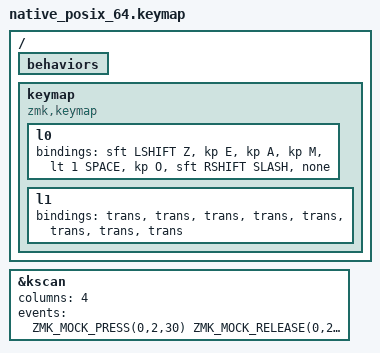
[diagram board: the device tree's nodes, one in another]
// Shift on Z and / with the real sft hold-tap: Shift with any other key,
// the key's own character only on a quick lone tap; a lone hold stays Shift.
// Shift goes down at key press (hold-while-undecided), so a tap is Shift, then z.
// Mock positions: row 0 = Z (sft LSHIFT), E, A, M; row 1 = Space (&lt 1), O, / (sft RSHIFT).
#include <dt-bindings/zmk/keys.h>
#include <behaviors.dtsi>
#include <dt-bindings/zmk/kscan_mock.h>

#include "real/&lt.dtsi"

/ {
    behaviors {
#include "real/sft.dtsi"
    };

    keymap {
        compatible = "zmk,keymap";
        l0 { bindings = <&sft LSHIFT Z &kp E &kp A &kp M &lt 1 SPACE &kp O &sft RSHIFT SLASH &none>; };
        l1 { bindings = <&trans &trans &trans &trans &trans &trans &trans &trans>; };
    };
};

&kscan {
    columns = <4>;
    events = <
        /* 1: a, Space tap, Z held 60 ms after Space up, tap O -> a, space, Shift+O */
        ZMK_MOCK_PRESS(0,2,30) ZMK_MOCK_RELEASE(0,2,40) ZMK_MOCK_PRESS(1,0,60) ZMK_MOCK_RELEASE(1,0,60)
        ZMK_MOCK_PRESS(0,0,50) ZMK_MOCK_PRESS(1,1,30) ZMK_MOCK_RELEASE(1,1,30) ZMK_MOCK_RELEASE(0,0,300)
        /* 2: a, then Z held as E (same hand) goes down -> a, Shift+E */
        ZMK_MOCK_PRESS(0,2,30) ZMK_MOCK_RELEASE(0,2,60) ZMK_MOCK_PRESS(0,0,40) ZMK_MOCK_PRESS(0,1,20)
        ZMK_MOCK_RELEASE(0,0,20) ZMK_MOCK_RELEASE(0,1,300)
        /* 3: a, then Z held as O (other hand) goes down -> a, Shift+O */
        ZMK_MOCK_PRESS(0,2,30) ZMK_MOCK_RELEASE(0,2,60) ZMK_MOCK_PRESS(0,0,40) ZMK_MOCK_PRESS(1,1,20)
        ZMK_MOCK_RELEASE(0,0,20) ZMK_MOCK_RELEASE(1,1,300)
        /* 4: idle, Z held, tap M -> Shift+M */
        ZMK_MOCK_PRESS(0,0,50) ZMK_MOCK_PRESS(0,3,30) ZMK_MOCK_RELEASE(0,3,30) ZMK_MOCK_RELEASE(0,0,300)
        /* 5: Z tapped alone -> Shift down and up, then z */
        ZMK_MOCK_PRESS(0,0,50) ZMK_MOCK_RELEASE(0,0,300)
        /* 6: Z held alone 400 ms, then released -> Shift only, no z */
        ZMK_MOCK_PRESS(0,0,400) ZMK_MOCK_RELEASE(0,0,300)
        /* 7: Z released before O goes down -> z o */
        ZMK_MOCK_PRESS(0,0,40) ZMK_MOCK_RELEASE(0,0,20) ZMK_MOCK_PRESS(1,1,30) ZMK_MOCK_RELEASE(1,1,300)
        /* 8: a, Space tap, / held 60 ms after Space up, tap E -> a, space, Shift+E */
        ZMK_MOCK_PRESS(0,2,30) ZMK_MOCK_RELEASE(0,2,40) ZMK_MOCK_PRESS(1,0,60) ZMK_MOCK_RELEASE(1,0,60)
        ZMK_MOCK_PRESS(1,2,50) ZMK_MOCK_PRESS(0,1,30) ZMK_MOCK_RELEASE(0,1,30) ZMK_MOCK_RELEASE(1,2,300)
        /* 9: a, then / held as O (same hand) goes down -> a, Shift+O */
        ZMK_MOCK_PRESS(0,2,30) ZMK_MOCK_RELEASE(0,2,60) ZMK_MOCK_PRESS(1,2,40) ZMK_MOCK_PRESS(1,1,20)
        ZMK_MOCK_RELEASE(1,2,20) ZMK_MOCK_RELEASE(1,1,300)
        /* 10: / tapped alone -> Shift down and up, then / */
        ZMK_MOCK_PRESS(1,2,50) ZMK_MOCK_RELEASE(1,2,300)
        /* 11: / held alone 400 ms, then released -> Shift only, no / */
        ZMK_MOCK_PRESS(1,2,400) ZMK_MOCK_RELEASE(1,2,300)
    >;
};
